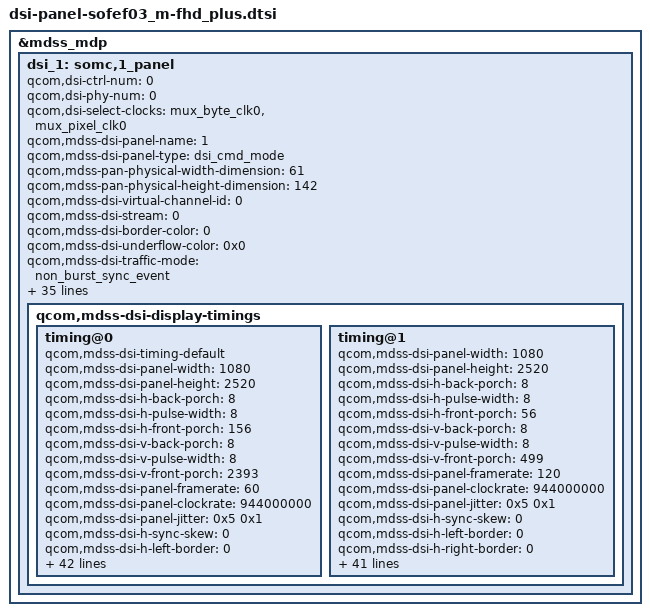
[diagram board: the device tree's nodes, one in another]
/* Copyright (c) 2015-2020, The Linux Foundation. All rights reserved.
 *
 * This program is free software; you can redistribute it and/or modify
 * it under the terms of the GNU General Public License version 2 and
 * only version 2 as published by the Free Software Foundation.
 *
 * This program is distributed in the hope that it will be useful,
 * but WITHOUT ANY WARRANTY; without even the implied warranty of
 * MERCHANTABILITY or FITNESS FOR A PARTICULAR PURPOSE.  See the
 * GNU General Public License for more details.
 */
&mdss_mdp {
	/* Samsung FHD OLED ID1 */
	dsi_1: somc,1_panel {
		qcom,dsi-ctrl-num = <0>;
		qcom,dsi-phy-num = <0>;
		qcom,dsi-select-clocks = "mux_byte_clk0", "mux_pixel_clk0";

		qcom,mdss-dsi-panel-name = "1";
		qcom,mdss-dsi-panel-type = "dsi_cmd_mode";
		qcom,mdss-pan-physical-width-dimension = <61>;
		qcom,mdss-pan-physical-height-dimension = <142>;
		qcom,mdss-dsi-virtual-channel-id = <0>;
		qcom,mdss-dsi-stream = <0>;
		qcom,mdss-dsi-border-color = <0>;
		qcom,mdss-dsi-underflow-color = <0x0>;
		qcom,mdss-dsi-traffic-mode = "non_burst_sync_event";
		qcom,mdss-dsi-bllp-eof-power-mode;
		qcom,mdss-dsi-bllp-power-mode;
		qcom,mdss-dsi-dma-trigger = "trigger_sw";
		qcom,mdss-dsi-mdp-trigger = "none";
		qcom,mdss-dsi-te-using-te-pin;
		qcom,mdss-dsi-te-pin-select = <1>;
		qcom,mdss-dsi-te-dcs-command = <1>;
		qcom,mdss-dsi-te-check-enable;
		qcom,mdss-dsi-tx-eot-append;
		qcom,mdss-dsi-wr-mem-start = <0x2c>;
		qcom,mdss-dsi-wr-mem-continue = <0x3c>;
		qcom,mdss-dsi-bpp = <24>;
		qcom,mdss-dsi-lane-0-state;
		qcom,mdss-dsi-lane-1-state;
		qcom,mdss-dsi-lane-2-state;
		qcom,mdss-dsi-lane-3-state;
		qcom,mdss-dsi-lp11-init;

		qcom,mdss-dsi-panel-peak-brightness = <4200000>;
		qcom,mdss-dsi-panel-blackness-level = <3230>;
		qcom,mdss-dsi-panel-hdr-enabled;
		qcom,mdss-dsi-panel-hdr-color-primaries = <1534 1590 3411 1589 1246 3521 689 250>;

		somc,pw-wait-before-on-lp11 = <10>;
		somc,mdss-dsi-touch-reset-sequence = <1 0>;
		qcom,mdss-dsi-reset-sequence = <1 10>;

		somc,pw-wait-after-off-lp11 = <1>;
		somc,pw-off-rst-b-seq = <0 0>;
		somc,pw-wait-after-off-touch-vddh = <10>;
		somc,pw-wait-down_period = <100>;

		qcom,dynamic-mode-switch-enabled;
		qcom,dynamic-mode-switch-type = "dynamic-resolution-switch-immediate";

		somc,area_count_table_size = <17>;
		somc,area_count_table = <0 68 136 204 273
				341 409 477 545 613
				681 749 818 886 954
				1022 1023>;

		qcom,mdss-dsi-display-timings {
			timing@0 {
				qcom,mdss-dsi-timing-default;
				qcom,mdss-dsi-panel-width = <1080>;
				qcom,mdss-dsi-panel-height = <2520>;
				qcom,mdss-dsi-h-back-porch = <8>;
				qcom,mdss-dsi-h-pulse-width = <8>;
				qcom,mdss-dsi-h-front-porch = <156>;
				qcom,mdss-dsi-v-back-porch = <8>;
				qcom,mdss-dsi-v-pulse-width = <8>;
				qcom,mdss-dsi-v-front-porch = <2393>;
				qcom,mdss-dsi-panel-framerate = <60>;
				qcom,mdss-dsi-panel-clockrate = <944000000>;
				qcom,mdss-dsi-panel-jitter = <0x5 0x1>;
				qcom,mdss-dsi-h-sync-skew = <0>;
				qcom,mdss-dsi-h-left-border = <0>;
				qcom,mdss-dsi-h-right-border = <0>;
				qcom,mdss-dsi-v-top-border = <0>;
				qcom,mdss-dsi-v-bottom-border = <0>;
				qcom,mdss-dsi-h-sync-pulse = <1>;
				qcom,mdss-dsi-on-command-state = "dsi_lp_mode";
				qcom,mdss-dsi-post-on-command-state = "dsi_lp_mode";
				qcom,mdss-dsi-off-command-state = "dsi_hs_mode";

				qcom,compression-mode = "dsc";
				qcom,mdss-dsc-slice-height = <30>;
				qcom,mdss-dsc-slice-width = <540>;
				qcom,mdss-dsc-slice-per-pkt = <2>;
				qcom,mdss-dsc-bit-per-component = <8>;
				qcom,mdss-dsc-bit-per-pixel = <8>;
				qcom,mdss-dsc-encoders = <2>;
				qcom,mdss-dsc-block-prediction-enable;

				qcom,mdss-dsi-on-command = [
					39 01 00 00 00 00 02 9D 01
					05 01 00 00 0A 00 01 11
					39 01 00 00 00 00 03 F0 5A 5A
					39 01 00 00 00 00 02 B0 09
					39 01 00 00 00 00 04 D5 00 00 00
					39 01 00 00 00 00 03 F0 A5 A5
					39 01 00 00 00 00 02 35 00
					39 01 00 00 00 00 05 2A 00 00 04 37
					39 01 00 00 00 00 05 2B 00 00 09 D7
					39 01 00 00 00 00 03 F0 5A 5A
					39 01 00 00 00 00 02 DF 83
					39 01 00 00 00 00 03 F0 A5 A5
					39 01 00 00 00 00 03 F0 5A 5A
					39 01 00 00 00 00 02 B0 01
					39 01 00 00 00 00 02 E6 01
					39 01 00 00 00 00 03 F0 A5 A5
					39 01 00 00 00 00 03 F0 5A 5A
					39 01 00 00 00 00 02 B0 02
					39 01 00 00 00 00 05 EC 02 00 1C 1C
					39 01 00 00 00 00 02 B0 0C
					39 01 00 00 00 00 03 EC 01 19
					39 01 00 00 00 00 03 F0 A5 A5
					39 01 00 00 00 00 02 53 20
					39 01 00 00 00 00 03 F0 5A 5A
					39 01 00 00 00 00 03 C2 2D 27
					39 01 00 00 3C 00 03 F0 A5 A5
					39 01 00 00 00 00 03 F0 5A 5A
					39 01 00 00 00 00 02 60 00
					39 01 00 00 00 00 03 F0 A5 A5
					];
				qcom,mdss-dsi-post-panel-on-command = [
					05 01 00 00 00 00 01 29];
				qcom,mdss-dsi-off-command = [
					05 01 00 00 14 00 01 28
					05 01 00 00 64 00 01 10];

				qcom,mdss-dsi-timing-switch-command = [
					05 01 00 00 00 00 01 28
					39 01 00 00 00 00 03 F0 5A 5A
					39 01 00 00 00 00 02 60 00
					39 01 00 00 00 00 03 F0 A5 A5
					05 01 00 00 00 00 01 29
					];
				qcom,mdss-dsi-timing-switch-command-state = "dsi_hs_mode";

				somc,mdss-dsi-hbm-on-command = [
					39 01 00 00 00 00 02 53 E8
					];
				somc,mdss-dsi-hbm-off-command = [
					39 01 00 00 11 00 02 53 28
					];
				somc,mdss-dsi-hbm-on-command-state = "dsi_lp_mode";
				somc,mdss-dsi-hbm-off-command-state = "dsi_lp_mode";

				somc,mdss-dsi-flm2-on-command = [
					39 01 00 00 00 00 03 F0 5A 5A
					39 01 00 00 00 00 03 C2 2D 27
					39 01 00 00 00 00 03 F0 A5 A5
					];
				somc,mdss-dsi-flm2-off-command = [
					39 01 00 00 00 00 03 F0 5A 5A
					39 01 00 00 00 00 03 C2 2D 07
					39 01 00 00 00 00 03 F0 A5 A5
					];
				somc,mdss-dsi-flm2-on-command-state = "dsi_lp_mode";
				somc,mdss-dsi-flm2-off-command-state = "dsi_lp_mode";
			};
			timing@1 {
				qcom,mdss-dsi-panel-width = <1080>;
				qcom,mdss-dsi-panel-height = <2520>;
				qcom,mdss-dsi-h-back-porch = <8>;
				qcom,mdss-dsi-h-pulse-width = <8>;
				qcom,mdss-dsi-h-front-porch = <56>;
				qcom,mdss-dsi-v-back-porch = <8>;
				qcom,mdss-dsi-v-pulse-width = <8>;
				qcom,mdss-dsi-v-front-porch = <499>;
				qcom,mdss-dsi-panel-framerate = <120>;
				qcom,mdss-dsi-panel-clockrate = <944000000>;
				qcom,mdss-dsi-panel-jitter = <0x5 0x1>;
				qcom,mdss-dsi-h-sync-skew = <0>;
				qcom,mdss-dsi-h-left-border = <0>;
				qcom,mdss-dsi-h-right-border = <0>;
				qcom,mdss-dsi-v-top-border = <0>;
				qcom,mdss-dsi-v-bottom-border = <0>;
				qcom,mdss-dsi-h-sync-pulse = <1>;
				qcom,mdss-dsi-on-command-state = "dsi_lp_mode";
				qcom,mdss-dsi-post-on-command-state = "dsi_lp_mode";
				qcom,mdss-dsi-off-command-state = "dsi_hs_mode";

				qcom,compression-mode = "dsc";
				qcom,mdss-dsc-slice-height = <30>;
				qcom,mdss-dsc-slice-width = <540>;
				qcom,mdss-dsc-slice-per-pkt = <2>;
				qcom,mdss-dsc-bit-per-component = <8>;
				qcom,mdss-dsc-bit-per-pixel = <8>;
				qcom,mdss-dsc-encoders = <2>;
				qcom,mdss-dsc-block-prediction-enable;

				qcom,mdss-dsi-on-command = [
					39 01 00 00 00 00 02 9D 01
					05 01 00 00 0A 00 01 11
					39 01 00 00 00 00 03 F0 5A 5A
					39 01 00 00 00 00 02 B0 09
					39 01 00 00 00 00 04 D5 00 00 00
					39 01 00 00 00 00 03 F0 A5 A5
					39 01 00 00 00 00 02 35 00
					39 01 00 00 00 00 05 2A 00 00 04 37
					39 01 00 00 00 00 05 2B 00 00 09 D7
					39 01 00 00 00 00 03 F0 5A 5A
					39 01 00 00 00 00 02 DF 83
					39 01 00 00 00 00 03 F0 A5 A5
					39 01 00 00 00 00 03 F0 5A 5A
					39 01 00 00 00 00 02 B0 01
					39 01 00 00 00 00 02 E6 01
					39 01 00 00 00 00 03 F0 A5 A5
					39 01 00 00 00 00 03 F0 5A 5A
					39 01 00 00 00 00 02 B0 02
					39 01 00 00 00 00 05 EC 02 00 1C 1C
					39 01 00 00 00 00 02 B0 0C
					39 01 00 00 00 00 03 EC 01 19
					39 01 00 00 00 00 03 F0 A5 A5
					39 01 00 00 00 00 02 53 20
					39 01 00 00 00 00 03 F0 5A 5A
					39 01 00 00 00 00 03 C2 2D 27
					39 01 00 00 3C 00 03 F0 A5 A5
					39 01 00 00 00 00 03 F0 5A 5A
					39 01 00 00 00 00 02 60 10
					39 01 00 00 00 00 03 F0 A5 A5
					];
				qcom,mdss-dsi-post-panel-on-command = [
					05 01 00 00 00 00 01 29];
				qcom,mdss-dsi-off-command = [
					05 01 00 00 14 00 01 28
					05 01 00 00 64 00 01 10];

				qcom,mdss-dsi-timing-switch-command = [
					05 01 00 00 00 00 01 28
					39 01 00 00 00 00 03 F0 5A 5A
					39 01 00 00 00 00 02 60 10
					39 01 00 00 00 00 03 F0 A5 A5
					05 01 00 00 00 00 01 29
					];
				qcom,mdss-dsi-timing-switch-command-state = "dsi_hs_mode";

				somc,mdss-dsi-hbm-on-command = [
					39 01 00 00 00 00 02 53 E8
					];
				somc,mdss-dsi-hbm-off-command = [
					39 01 00 00 11 00 02 53 28
					];
				somc,mdss-dsi-hbm-on-command-state = "dsi_lp_mode";
				somc,mdss-dsi-hbm-off-command-state = "dsi_lp_mode";

				somc,mdss-dsi-flm2-on-command = [
					39 01 00 00 00 00 03 F0 5A 5A
					39 01 00 00 00 00 03 C2 2D 27
					39 01 00 00 00 00 03 F0 A5 A5
					];
				somc,mdss-dsi-flm2-off-command = [
					39 01 00 00 00 00 03 F0 5A 5A
					39 01 00 00 00 00 03 C2 2D 07
					39 01 00 00 00 00 03 F0 A5 A5
					];
				somc,mdss-dsi-flm2-on-command-state = "dsi_lp_mode";
				somc,mdss-dsi-flm2-off-command-state = "dsi_lp_mode";
			};
		};
	};
};
